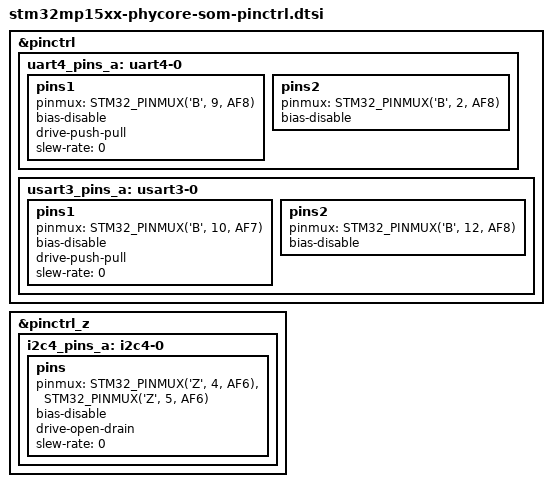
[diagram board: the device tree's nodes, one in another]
// SPDX-License-Identifier: (GPL-2.0+ OR BSD-3-Clause)
/*
 * Copyright (C) 2020 PHYTEC Messtechnik GmbH
 * Author: Dom Vovard <dom.vovard@linrt.com>
 *	   Christophe Parant <c.parant@phytec.fr>
 */

#include <dt-bindings/pinctrl/stm32-pinfunc.h>

&pinctrl {

	uart4_pins_a: uart4-0 {
		pins1 {
			pinmux = <STM32_PINMUX('B', 9, AF8)>; /* UART4_TX */
			bias-disable;
			drive-push-pull;
			slew-rate = <0>;
		};
		pins2 {
			pinmux = <STM32_PINMUX('B', 2, AF8)>; /* UART4_RX */
			bias-disable;
		};
	};

	usart3_pins_a: usart3-0 {
		pins1 {
			pinmux = <STM32_PINMUX('B', 10, AF7)>; /* USART3_TX */
			bias-disable;
			drive-push-pull;
			slew-rate = <0>;
		};
		pins2 {
			pinmux = <STM32_PINMUX('B', 12, AF8)>; /* USART3_RX */
			bias-disable;
		};
	};
};

&pinctrl_z {

	i2c4_pins_a: i2c4-0 {
		pins {
			pinmux = <STM32_PINMUX('Z', 4, AF6)>, /* I2C4_SCL */
				 <STM32_PINMUX('Z', 5, AF6)>; /* I2C4_SDA */
			bias-disable;
			drive-open-drain;
			slew-rate = <0>;
		};
	};
};
